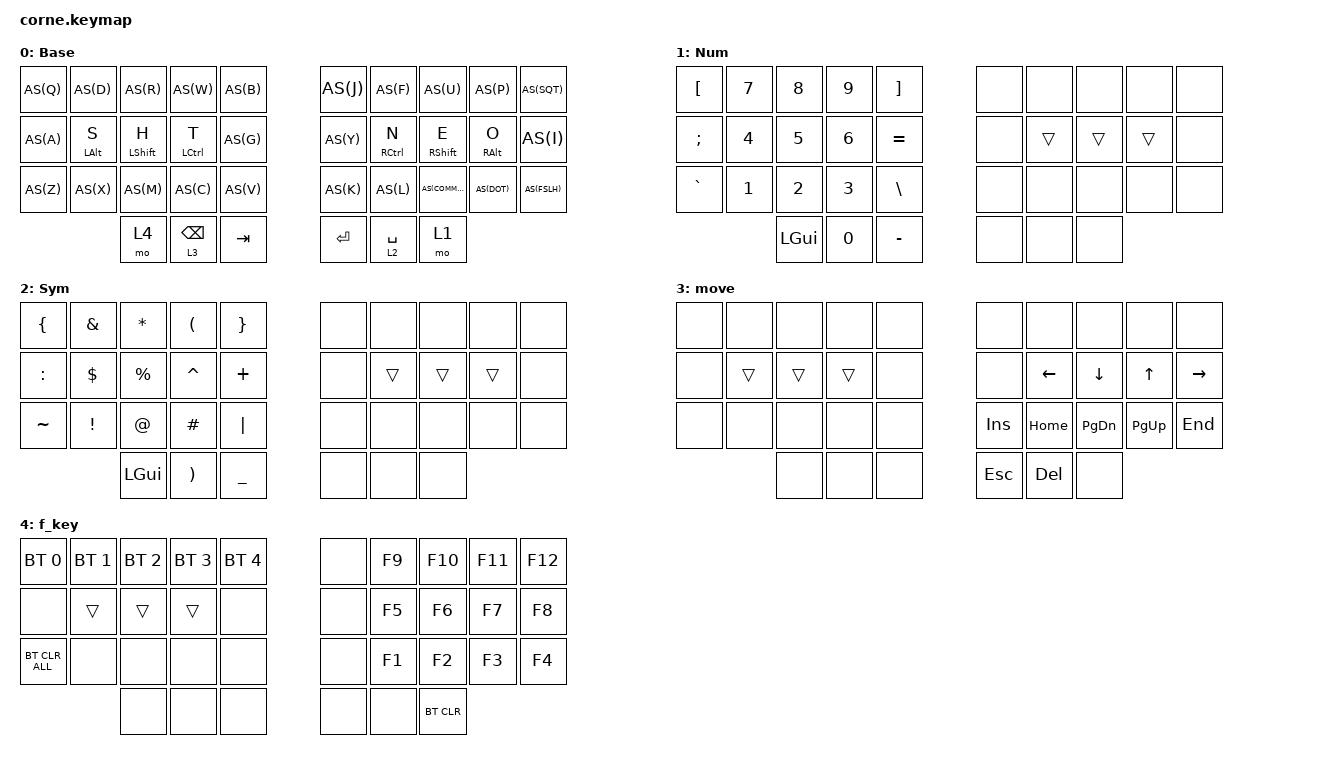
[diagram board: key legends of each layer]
/*
 * Copyright (c) 2020 The ZMK Contributors
 *
 * SPDX-License-Identifier: MIT
 */

#include <behaviors.dtsi>
#include <dt-bindings/zmk/keys.h>
#include <dt-bindings/zmk/bt.h>
#include <dt-bindings/zmk/behaviors.h>


#define AS(keycode) &as LS(keycode) keycode

/ {
    chosen {
        zmk,physical-layout = &foostan_corne_5col_layout;
    };

    behaviors {
        as: auto_shift {
            compatible = "zmk,behavior-hold-tap";
            #binding-cells = <2>;
            tapping-term-ms = <200>;
            quick-tap-ms = <0>;
            flavor = "tap-preferred";
            bindings = <&kp>, <&kp>;
        };
        mt: mod_tap {
            compatible = "zmk,behavior-hold-tap";
            #binding-cells = <2>;
            flavor = "balanced";
            require-prior-idle-ms = <100>;
            tapping-term-ms = <400>;
            bindings = <&kp>, <&kp>;
            display-name = "Mod-Tap";
        };
        lt: layer_tap {
            compatible = "zmk,behavior-hold-tap";
            #binding-cells = <2>;
            flavor = "tap-preferred";
            tapping-term-ms = <200>;
            bindings = <&mo>, <&kp>;
            display-name = "Layer-Tap";
        };
    };
    combos {
        compatible = "zmk,combos";
        combo_pscr {
            require-prior-idle-ms = <150>;
            timeout-ms = <150>;
            key-positions = <1 2>;
            bindings = <&kp PSCRN>;
        };
        combo_caps {
            require-prior-idle-ms = <150>;
            timeout-ms = <150>;
            key-positions = <7 8>;
            bindings = <&kp CAPSLOCK>;
        };
    };
        keymap {
                compatible = "zmk,keymap";

                default_layer {
// -----------------------------------------------------------------------------------------
// |  Q  |  D  |  R  |  W  |  B  |     |  J  |  F   |  U   |  P   | ' |
// |  A  | LALT S | LSHIFT H | LCTRL T |  G  |     |  Y  | RCTRL N | RSHIFT E | RALT O | I | 
// |  Z  |  X  |  M  |  C  |  V  |     |  K  |  L   | ,    | .    | / |
//      | LYR4 | BSPC LYR3 | TAB |     | ENT | SPACE LYR1 | LYR2 |
                        display-name = "Base";
                        bindings = <
   AS(Q) AS(D) AS(R) AS(W) AS(B)     AS(J)   AS(F)  AS(U)     AS(P)     AS(SQT)
   AS(A) &mt LALT S &mt LSHIFT H &mt LCTRL T AS(G)  AS(Y)   &mt RCTRL N  &mt RSHIFT E   &mt RALT O     AS(I)
   AS(Z) AS(X) AS(M) AS(C) AS(V)     AS(K)   AS(L)  AS(COMMA) AS(DOT)   AS(FSLH)
        &mo 4 &lt 3 BSPC &kp TAB     &kp RET &lt 2 SPACE &mo 1
                        >;
                };

                num_layer {
// -----------------------------------------------------------------------------------------
// | [ |  7 |  8   |  9  |  ]  |     |     |     |     |      |      |
// | ; |  4 |  5   |  6  |  =  |     |     | RCTRL | RSHIFT | RALT |     |
// | ` |  1 |  2   |  3  |  \  |     |     |     |     |      |      |
//               | LGUI | 0 | - |     |     |     |     |
                        display-name = "Num";
                        bindings = <

   &kp LBKT    &kp N7     &kp N8     &kp N9     &kp RBKT        &none    &none    &none    &none    &none
   &kp SEMI    &kp N4     &kp N5     &kp N6     &kp EQUAL       &none    &trans   &trans   &trans   &none
   &kp GRAVE   &kp N1     &kp N2     &kp N3     &kp BSLH        &none    &none    &none    &none    &none
                          &kp LGUI   &kp N0     &kp MINUS       &none    &none    &none
                        >;
                };


                sym_layer {
// -----------------------------------------------------------------------------------------
// |  {  |  &  |  *  |  (  |  }  |     |  |  |  |  |  |
// |  :  |  $  |  %  |  ^  |  +  |     |  |RCTRL | RSHIFT | RALT |  |
// |  ~  |  !  |  @  |  #  |  |  |     |  |  |  |  |  |
//             |  )  |  _  | SPC |     |  |  |  |
                        display-name = "Sym";
                        bindings = <
   &kp LBRC     &kp AMPS    &kp STAR    &kp LPAR    &kp RBRC        &none    &none    &none    &none    &none
   &kp COLON    &kp DOLLAR  &kp PERCENT &kp CARET   &kp PLUS        &none    &trans   &trans   &trans   &none
   &kp TILDE    &kp EXCL    &kp AT_SIGN &kp HASH    &kp PIPE        &none    &none    &none    &none    &none     
                            &kp LGUI    &kp RPAR    &kp UNDERSCORE  &none    &none    &none
                        >;
                };
                move_layer {
// -----------------------------------------------------------------------------------------
// |  |  |  |  |  |     |     |     |     |     |    |
// |  |  |  |  |  |     | LFT | DWN |   UP  |  RGT  |      |
// |  |  |  |  |  |     | INS | HOME| PG_DN | PG_UP |  END |
//       |  |  |  |     | ESC | DEL |   |
                        display-name = "move";
                        bindings = <

   &none    &none    &none    &none    &none      &none    &none    &none    &none    &none 
   &none    &trans   &trans   &trans   &none      &none    &kp LEFT &kp DOWN &kp UP    &kp RIGHT
   &none    &none    &none    &none    &none      &kp INS  &kp HOME &kp PG_DN &kp PG_UP &kp END
                     &none    &none    &none      &kp ESC  &kp DEL  &none
                        >;
                };
                f_key_layer {
// -----------------------------------------------------------------------------------------
//  |  |  |  |  |  |             | F9 | F10 | F11 | F12 |  |
//  |  |RCTRL | RSHIFT | RALT |  | F5 | F6  | F7  | F8  |  |
//  |  |  |  |  |  |             | F1 | F2  | F3  | F4  |  |
//        |  |  |  |             |BT_CLR |  |     |
                        display-name = "f_key";
                        bindings = <

   &bt BT_SEL 0    &bt BT_SEL 1    &bt BT_SEL 2    &bt BT_SEL 3    &bt BT_SEL 4      &none   &kp F9   &kp F10   &kp F11   &kp F12 
   &none    &trans   &trans   &trans   &none      &none   &kp F5   &kp F6    &kp F7    &kp F8
   &bt BT_CLR_ALL    &none    &none    &none    &none      &none   &kp F1   &kp F2    &kp F3    &kp F4
                     &none    &none    &none      &none   &none  &bt BT_CLR
                        >;
                };

                extra_1 {
                        status = "reserved";
                };

                extra_2 {
                        status = "reserved";
                };

                extra_3 {
                        status = "reserved";
                };
        };
};
